# DSP_EDMA_TPTC0 register map
Vendor: Texas Instruments
Peripheral module from a debugger description file (folder DRA75x_DRA74x).
Registers are 32-bit, read-only, reset 0x0 unless marked. A register's access mark holds for its fields unless they carry their own. Offsets are as the file gives them; lines under a group give offsets from that group; [hi:lo] are bit positions; {n}, {i} and the like mark numbered series; 'fields as' and 'values as' point back to an identical list; <NAME> marks a mode.

## DSP_EDMA_TPTC0
0x00 EDMA_TPTCn_PID reset not defined — Peripheral ID Register
  [31:0] REVISION — IP Revision
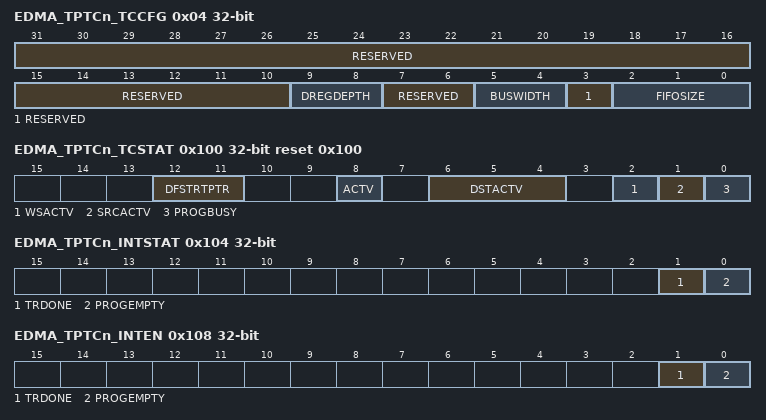
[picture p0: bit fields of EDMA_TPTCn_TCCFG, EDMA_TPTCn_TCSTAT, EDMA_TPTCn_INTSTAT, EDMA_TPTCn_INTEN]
0x04 EDMA_TPTCn_TCCFG (reset mask 0xFFFFFCC8) — TC Configuration Register
  [31:10] RESERVED — Reads return 0's
  [9:8] DREGDEPTH — Dst Register FIFO Depth Parameterization
    0=FIFODEPTH_1 (1 entry); 1=FIFODEPTH_2 (2 entries); 2=FIFODEPTH_4 (4 entries)
  [7:6] RESERVED — Reads return 0's
  [5:4] BUSWIDTH — Bus Width Parameterization
    0=BW_32BIT (32-bit); 1=BW_64BIT (64-bit); 2=BW_128BIT (128-bit)
  [3] RESERVED — Reads return 0's
  [2:0] FIFOSIZE — Fifo Size Parameterization
    0=FIFO_32_BYTE (32 byte FIFO); 1=FIFO_64_BYTE (64 byte FIFO); 2=FIFO_256_BYTE (128 byte FIFO); 3=FIFO_512_BYTE (256 byte FIFO); 4=FIFO_128_BYTE (512 byte FIFO)
0x100 EDMA_TPTCn_TCSTAT access not given reset 0x100 — TC Status Register
  [12:11] DFSTRTPTR ro — Dst FIFO Start Pointer Represents the offset to the head entry of Dst Register FIFO, in units of *entries*. Legal values = 0x0 to 0x3
  [8] ACTV ro — Channel Active Channel Active is a logical-OR of each of the *BUSY/ACTV signals. The ACTV bit must remain high through the life of a TR.
    0=Channel_is_idle; 1=Channel_is_busy
  [6:4] DSTACTV ro — Destination Active State Specifies the number of TRs that are resident in the Dst Register FIFO at a given instant. Legal values are constrained by the DSTREGDEPTH parameter.
  [2] WSACTV ro — Write Status Active
    0=Write status is not pending. Write status has been received for all previously issued write commands.; 1=Write Status is pending. Write status has not been received for all previously issued write commands.
  [1] SRCACTV ro — Source Active State
    0=TR_FIFO_(DSTFULL_0 (Source Active set is idle. Any TR written to Prog Set will immediately transition to Source Active set as long as the Dst FIFO Set is not full (DSTFULL == 1).); 1=Source Active set is busy either performing read transfers or waiting to perform read transfers for current Transfer Request
  [0] PROGBUSY ro — Program Register Set Busy
    0=Program set idle and is available for programming; 1=Program set busy. User should poll for PROGBUSY equal to '0' prior to re-programming the Program Register set.
0x104 EDMA_TPTCn_INTSTAT access not given — Interrupt Status Register
  [1] TRDONE ro — TR Done Event Status
    0=Condition_not_detected; 1=TC_TRDONE_TR._INTCLR.TRDONE_1 (Set when TC has completed a Transfer Request. TRDONE should be set when the write status is returned for the final write of a TR. Cleared when write '1' to INTCLR.TRDONE register bit.)
  [0] PROGEMPTY ro — Program Set Empty Event Status
    0=Condition_not_detected; 1=Set when Program Register set transitions to empty state. Cleared when write '1' to [0] PROGEMPTY register bit.
0x108 EDMA_TPTCn_INTEN access per field — Interrupt Enable Register
  [1] TRDONE rw — TR Done Event Enable
    0=TRDONE_Event_is_disabled; 1=TRDONE Event is enabled, and contributes to interrupt generation
  [0] PROGEMPTY rw — Program Set Empty Event Enable
    0=PROGEMPTY_Event_is_disabled; 1=PROGEMPTY Event is enabled, and contributes to interrupt generation
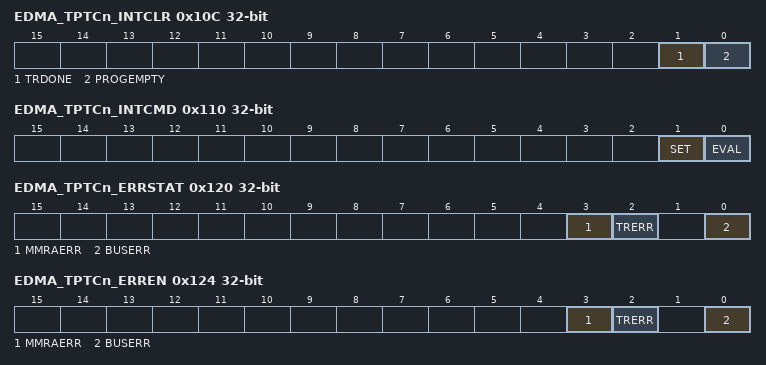
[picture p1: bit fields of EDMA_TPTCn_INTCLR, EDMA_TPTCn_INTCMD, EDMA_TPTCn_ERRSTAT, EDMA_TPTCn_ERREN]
0x10C EDMA_TPTCn_INTCLR access per field — Interrupt Clear Register
  [1] TRDONE wo — TR Done Event Clear
    0=have_no_effect; 1=Clear
  [0] PROGEMPTY wo — Program Set Empty Event Clear
    0=have_no_effect; 1=Clear
0x110 EDMA_TPTCn_INTCMD access per field — Interrupt Command Register
  [1] SET wo — Set TPTC interrupt
    0=have_no_affect; 1=SET_TPTC_1 (SET causes TPTC interrupt to be pulsed unconditionally)
  [0] EVAL wo — Evaluate state of TPTC interrupt
    0=have_no_affect; 1=TPTC_1 (causes TPTC interrupt to be pulsed if any of the bits are set to '1'.)
0x120 EDMA_TPTCn_ERRSTAT access not given — Error Status Register
  [3] MMRAERR ro — MR Address Error
    0=Condition_not_detected; 1=User attempted to read or write to invalid address configuration mMemory map. (Is only be set for non-emulation accesses). No additional error information is recorded.
  [2] TRERR ro — TR Error: TR detected that violates FIFO Mode transfer (SAM or DAM is '1') alignment rules or has ACNT or BCNT == 0. No additional error information is recorded.
  [0] BUSERR ro — Bus Error Event
    0=Condition_not_detected; 1=TC_1 (TC has detected an error code on the write response bus or read response bus. Error information is stored in Error Details Register ().)
0x124 EDMA_TPTCn_ERREN access not given — Error Enable Register
  [3] MMRAERR rw — Interrupt enable forEDMA_TPTCn_ERRSTAT[3] MMRAERR
    0=BUSERR_is_disabled; 1=MMRAERR_TPTC_1 (MMRAERR is enabled, and contributes to the TPTC error interrupt generation.)
  [2] TRERR rw — Interrupt enable forEDMA_TPTCn_ERRSTAT[2] TRERR
    0=BUSERR_is_disabled; 1=TRERR_TPTC_1 (TRERR is enabled, and contributes to the TPTC error interrupt generation.)
  [0] BUSERR rw — Interrupt enable forEDMA_TPTCn_ERRSTAT[0] BUSERR
    0=BUSERR_is_disabled; 1=BUSERR_TPTC_1 (BUSERR is enabled, and contributes to the TPTC error interrupt generation.)
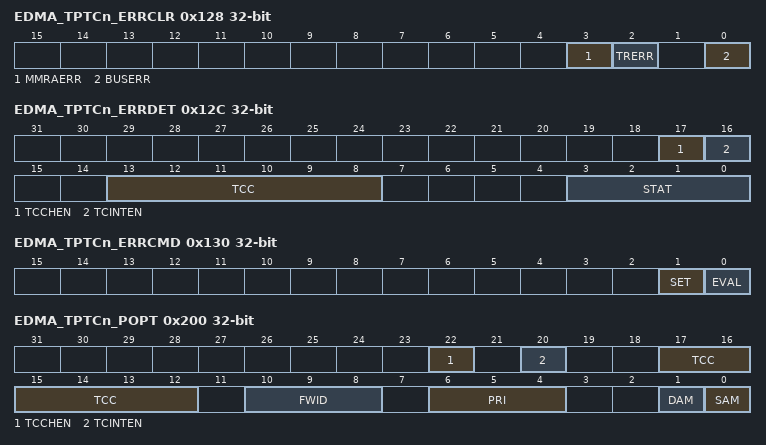
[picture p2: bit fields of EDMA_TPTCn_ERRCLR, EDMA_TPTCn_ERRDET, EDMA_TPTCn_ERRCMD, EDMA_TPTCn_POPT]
0x128 EDMA_TPTCn_ERRCLR access not given — Error Clear Register
  [3] MMRAERR wo — Interrupt clear forEDMA_TPTCn_ERRSTAT[3] MMRAERR
    0=have_no_effect; 1=MMRAERR_MMRAERR_ERRDET_1 (to clear[3] MMRAERR bit. Write of '1' to [3] MMRAERR does not clear the ERRDET register.)
  [2] TRERR wo — Interrupt clear forEDMA_TPTCn_ERRSTAT[2] TRERR
    0=have_no_effect; 1=TRERR_TRERR_ERRDET_1 (to clear[2] TRERR bit. Write of '1' to [2] TRERR does not clear the ERRDET register.)
  [0] BUSERR wo — Interrupt clear forEDMA_TPTCn_ERRSTAT[0] BUSERR
    0=have_no_effect; 1=BUSERR_BUSERR_ERRDET_1 (to clear[0] BUSERR bit Write of '1' to [0] BUSERR clears the ERRDET register.)
0x12C EDMA_TPTCn_ERRDET access not given — Error Details Register
  [17] TCCHEN ro — Contains theEDMA_TPCC_OPT_n[17] TCCHEN value programmed by the user for the Read or Write transaction that resulted in an error.
  [16] TCINTEN ro — Contains theEDMA_TPCC_OPT_n[16] TCINTEN value programmed by the user for the Read or Write transaction that resulted in an error.
  [13:8] TCC ro — Transfer Complete Code: Contains theEDMA_TPCC_OPT_n[13:8] TCC value programmed by the user for the Read or Write transaction that resulted in an error.
  [3:0] STAT ro — Transaction Status: Stores the non-zero status/error code that was detected on the read status or write status bus. MS-bit effectively serves as the read vs. write error code. If read status and write status are returned on the same cycle, then the TC chooses non-zero version. If both are non-zero then write status is treated as higher priority. Encoding of errors matches the CBA spec and is summarized here: 0xF =
0x130 EDMA_TPTCn_ERRCMD access per field — Error Command Register
  [1] SET wo — Set TPTC error interrupt
    0=have_no_affect; 1=SET_TPTC_1 (to SET causes TPTC error interrupt to be pulsed unconditionally.)
  [0] EVAL wo — Evaluate state of TPTC error interrupt Write of '1'
    0=have_no_affect; 1=EVAL_TPTC_1 (to EVAL causes TPTC error interrupt to be pulsed if any of the bits are set to '1'.)
0x140 EDMA_TPTCn_RDRATE access per field — Read Rate Register
  [2:0] RDRATE rw — Read Rate Control: Controls the number of cycles between read commands. This is a global setting that applies to all TRs for this TC.
0x200 EDMA_TPTCn_POPT access per field — Program Set Options
  [22] TCCHEN rw — Transfer complete chaining enable
    0=Transfer_complete_chaining_is_disabled; 1=Transfer_complete_chaining_is_enabled
  [20] TCINTEN rw — Transfer complete interrupt enable
    0=Transfer complete interrupt is disabled; 1=Transfer_complete_interrupt_is_enabled
  [17:12] TCC rw — Transfer Complete Code: The 6-bit code is used to set the relevant bit in CER orEDMA_TPCC_IPR of the TPCC module.
  [10:8] FWID rw — FIFO width control: Applies if either SAM or DAM is set to FIFO mode.
  [6:4] PRI rw — Transfer Priority: 0x0: Priority 0 - Highest priority 0x1: Priority 1 ... 0x7: Priority 7 - Lowest priority
  [1] DAM rw — Destination Address Mode within an array
    0=INCR,_0 (INCR, Destination addressing within an array increments.); 1=FIFO,_FIFO_1 (FIFO, Destination addressing within an array wraps around upon reaching FIFO width.)
  [0] SAM rw — Source Address Mode within an array
    0=INCR,_0 (INCR, Source addressing within an array increments.); 1=FIFO,_FIFO_1 (FIFO, Source addressing within an array wraps around upon reaching FIFO width.)
0x204 EDMA_TPTCn_PSRC rw — Program Set Source Address
  [31:0] SADDR — Source address for Program Register Set
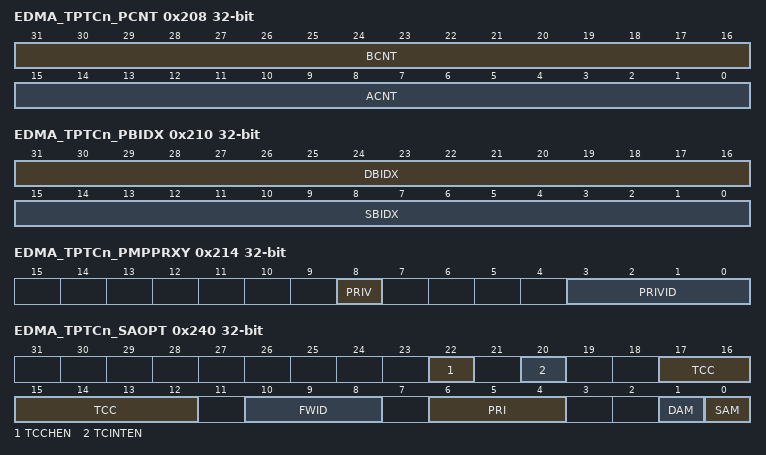
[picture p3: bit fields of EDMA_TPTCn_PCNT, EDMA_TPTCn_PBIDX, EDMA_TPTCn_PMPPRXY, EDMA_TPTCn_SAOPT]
0x208 EDMA_TPTCn_PCNT rw — Program Set Count
  [31:16] BCNT — B-Dimension count. Number of arrays to be transferred, where each array is ACNT in length.
  [15:0] ACNT — A-Dimension count. Number of bytes to be transferred in first dimension.
0x20C EDMA_TPTCn_PDST rw — Program Set Destination Address
  [31:0] DADDR — Destination address for Program Register Set
0x210 EDMA_TPTCn_PBIDX rw — Program Set B-Dim Idx
  [31:16] DBIDX — Dest B-Idx for Program Register Set: B-Idx offset between Destination arrays: Represents the offset in bytes between the starting address of each destination array (recall that there are BCNT arrays of ACNT elements). DBIDX is always used, regardless of whether DAM is Increment or FIFO mode.
  [15:0] SBIDX — Source B-Idx for Program Register Set: B-Idx offset between Source arrays: Represents the offset in bytes between the starting address of each source array (recall that there are BCNT arrays of ACNT elements). SBIDX is always used, regardless of whether SAM is Increment or FIFO mode.
0x214 EDMA_TPTCn_PMPPRXY access not given — Program Set Memory Protect Proxy
  [8] PRIV ro — Privilege Level
    0=User_level_privilege; 1=BIDX_PRIV_SA_DF_ID_PRIV_DMA_1 (Supervisor level privilege.PRIV is always updated with the value from the configuration bus privilege field on any/every write to Program Set BIDX Register (trigger register). The PRIV value for the SA Set and DF Set are copied from the value in the Program set along with the remainder of the parameter values. The privilege ID is issued on the VBusM read and write command bus such that the target endpoints can perform mMemory protection checks based on the PRIV of the external host that sets up the DMA transaction.)
  [3:0] PRIVID ro — Privilege ID: EDMA_TPTCn_PMPPRXY.PRIVID is always updated with the value from configuration bus privilege ID field on any/every write to Program Set BIDX Register (trigger register). The PRIVID value for the SA Set and DF Set are copied from the value in the Program set along with the remainder of the parameter values. The privilege ID is issued on the VBusM read and write command bus such that the target endpoints can perform mMemory protection checks based on the privid of the external host that sets up the DMA transaction.
0x240 EDMA_TPTCn_SAOPT access not given — Source Actve Set Options
  [22] TCCHEN ro — Transfer complete chaining enable
    values as EDMA_TPTCn_POPT.TCCHEN
  [20] TCINTEN ro — Transfer complete interrupt enable
    values as EDMA_TPTCn_POPT.TCINTEN
  [17:12] TCC ro — Transfer Complete Code The 6-bit code is used to set the relevant bit in EDMA_TPCC_CER or EDMA_TPCC_IPR of the TPCC module.
  [10:8] FWID ro — FIFO width control Applies if either SAM or DAM is set to FIFO mode.
  [6:4] PRI ro — Transfer Priority... .
    0=Priority_0_-_Highest_priority; 1=Priority_1; 7=Priority_7_-_Lowest_priority
  [1] DAM ro — Destination Address Mode within an array
    values as EDMA_TPTCn_POPT.DAM
  [0] SAM ro — Source Address Mode within an array
    values as EDMA_TPTCn_POPT.SAM
0x244 EDMA_TPTCn_SASRC — Source Active Set Source Address
  [31:0] SADDR — Source address for Source Active Register Set: Initial value is copied from EDMA_TPTCn_PSRC.SADDR. TC updates value according to source addressing mode (EDMA_TPCC_OPT_n.SAM) and/or source index value (BIDX.SBIDX) after each read command is issued. When a TR is complete, the final value should be the address of the last read command issued.
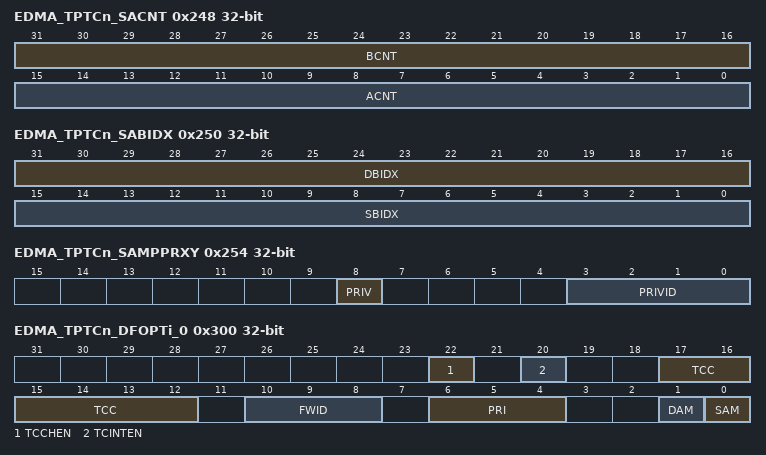
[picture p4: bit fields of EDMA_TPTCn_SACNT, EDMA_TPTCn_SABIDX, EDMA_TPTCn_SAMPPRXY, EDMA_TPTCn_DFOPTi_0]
0x248 EDMA_TPTCn_SACNT — Source Active Set Count
  [31:16] BCNT — B-Dimension count: Number of arrays to be transferred, where each array is ACNT in length. Count Remaining for Source Active Register Set. Represents the amount of data remaining to be read. Initial value is copied from EDMA_TPTCn_PCNT. TC decrements ACNT and BCNT as necessary after each read command is issued. Final value should be 0 when TR is complete.
  [15:0] ACNT — A-Dimension count: Number of bytes to be transferred in first dimension. Count Remaining for Source Active Register Set. Represents the amount of data remaining to be read. Initial value is copied from EDMA_TPTCn_PCNT. TC decrements ACNT and BCNT as necessary after each read command is issued. Final value should be 0 when TR is complete.
0x24C EDMA_TPTCn_SADST — Source Active Destination Address Register Reserved, return 0x0 w/o AERROR
  [31:0] DADDR — Destination address is not applicable for Source Active Register Set. Reads return 0x0
0x250 EDMA_TPTCn_SABIDX — Source Active Set B-Dim Idx
  [31:16] DBIDX — Destination B-Idx for Source Active Register Set. Value copied from EDMA_TPTCn_PBIDX: B-Idx offset between Destination arrays: Represents the offset in bytes between the starting address of each destination array (recall that there are BCNT arrays of ACNT elements). DBIDX is always used, regardless of whether DAM is Increment or FIFO mode.
  [15:0] SBIDX — Source B-Idx for Source Active Register Set. Value copied fromEDMA_TPTCn_PBIDX: B-Idx offset between Source arrays: Represents the offset in bytes between the starting address of each source array (recall that there are BCNT arrays of ACNT elements). SBIDX is always used, regardless of whether SAM is Increment or FIFO mode.
0x254 EDMA_TPTCn_SAMPPRXY access not given — Source Active Set Mem Protect Proxy
  [8] PRIV ro — Privilege Level
    0=User_level_privilege; 1=SAMPPRXY.PRIV_BIDX_PRIV_SA_DF_ID_PRIV_DMA_1 (Supervisor level privilege SAMPPRXY.PRIV is always updated with the value from the configuration bus privilege field on any/every write to Program Set BIDX Register (trigger register). The PRIV value for the SA Set and DF Set are copied from the value in the Program set along with the remainder of the parameter values. The privilege ID is issued on the VBusM read and write command bus such that the target endpoints can perform mMemory protection checks based on the PRIV of the external host that sets up the DMA transaction.)
  [3:0] PRIVID ro — Privilege ID SAMPPRXY.PRIVID is always updated with the value from configuration bus privilege ID field on any/every write to Program Set BIDX Register (trigger register). The PRIVID value for the SA Set and DF Set are copied from the value in the Program set along with the remainder of the parameter values. The privilege ID is issued on the VBusM read and write command bus such that the target endpoints can perform mMemory protection checks based on the privid of the external host that sets up the DMA transaction.
0x258 EDMA_TPTCn_SACNTRLD access not given — Source Active Set Count Reload
  [15:0] ACNTRLD ro — A-Cnt Reload value for Source Active Register set. Value copied from EDMA_TPTCn_PCNT[15:0] ACNT: Represents the originally programmed value of ACNT. The Reload value is used to reinitialize ACNT after each array is serviced (i.e., ACNT decrements to 0). by the Src offset in bytes between the starting address of each source array (recall that there are BCNT arrays of ACNT bytes)
0x25C EDMA_TPTCn_SASRCBREF — Source Active Set Source Address A-Reference
  [31:0] SADDRBREF — Source address reference for Source Active Register Set: Represents the starting address for the array currently being read. The next array's starting address is calculated as the 'reference address' plus the 'source b-idx' value.
0x260 EDMA_TPTCn_SADSTBREF — Source Active Destination Address B-Reference Register Reserved, return 0x0 w/o AERROR
  [31:0] DADDRBREF — Destination address reference is not applicable for Src Active Register Set. Reads return 0x0.
0x280 EDMA_TPTCn_DFCNTRLD access not given — Destination FIFO Set Count Reload
  [15:0] ACNTRLD ro — A-Cnt Reload value for Destination FIFO Register set. Value copied fromEDMA_TPTCn_PCNT[15:0] ACNT: Represents the originally programmed value of ACNT. The Reload value is used to reinitialize ACNT after each array is serviced (i.e., ACNT decrements to 0). by the Src offset in bytes between the starting address of each source array (recall that there are BCNT arrays of ACNT bytes)
0x284 EDMA_TPTCn_DFSRCBREF — Destination FIFO Set Destination Address B Reference Reserved, return 0x0 w/o AERROR
  [31:0] SADDRBREF — Source address reference is not applicable for Dst FIFO Register Set. Reads return 0x0.
0x288 EDMA_TPTCn_DFDSTBREF — Destination FIFO Set Destination Address A-Reference
  [31:0] DADDRBREF — Destination address reference for Dst FIFO Register Set: Represents the starting address for the array currently being written. The next array's starting address is calculated as the 'reference address' plus the 'dest bidx' value.
0x300 EDMA_TPTCn_DFOPTi_0 access not given — Destination FIFO Set Options
  [22] TCCHEN ro — Transfer complete chaining enable
    values as EDMA_TPTCn_POPT.TCCHEN
  [20] TCINTEN ro — Transfer complete interrupt enable
    values as EDMA_TPTCn_POPT.TCINTEN
  [17:12] TCC ro — Transfer Complete Code The 6-bit code is used to set the relevant bit in CER or EDMA_TPCC_IPR of the TPCC module.
  [10:8] FWID ro — FIFO width control Applies if either SAM or DAM is set to FIFO mode.
  [6:4] PRI ro — Transfer Priority... .
    values as EDMA_TPTCn_SAOPT.PRI
  [1] DAM ro — Destination Address Mode within an array
    0=INCR,_0 (INCR, Dst addressing within an array increments.); 1=FIFO,_FIFO_1 (FIFO, Dst addressing within an array wraps around upon reaching FIFO width.)
  [0] SAM ro — Source Address Mode within an array
    values as EDMA_TPTCn_POPT.SAM
0x304 EDMA_TPTCn_DFSRCi_0 — Destination FIFO source address register Reserved, return 0x0 w/o AERROR
  [31:0] SADDR — Source address is not applicable for Dst FIFO Register Set: Reads return 0x0.
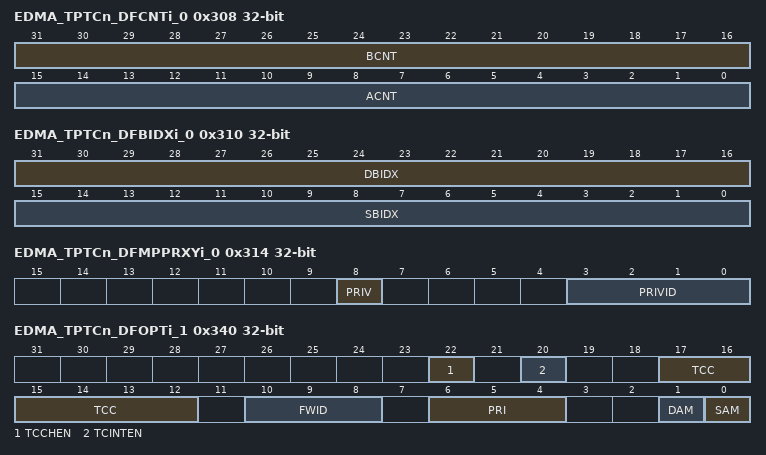
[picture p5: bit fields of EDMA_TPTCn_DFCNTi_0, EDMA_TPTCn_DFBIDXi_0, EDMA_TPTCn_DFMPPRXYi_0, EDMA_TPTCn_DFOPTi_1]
0x308 EDMA_TPTCn_DFCNTi_0 — Destination FIFO count register
  [31:16] BCNT — B-Count Remaining for Dst Register Set: Number of arrays to be transferred, where each array is ACNT in length. Represents the amount of data remaining to be written. Initial value is copied from EDMA_TPTCn_PCNT. TC decrements ACNT and BCNT as necessary after each write dataphase is issued. Final value should be 0 when TR is complete.
  [15:0] ACNT — A-Count Remaining for Dst Register Set: Number of bytes to be transferred in first dimension. Represents the amount of data remaining to be written. Initial value is copied from EDMA_TPTCn_PCNT. TC decrements ACNT and BCNT as necessary after each write dataphase is issued. Final value should be 0 when TR is complete.
0x30C EDMA_TPTCn_DFDSTi_0 — The destination FIFO destination address register
  [31:0] DADDR — Destination address for Dst FIFO Register Set: Initial value is copied from EDMA_TPTCn_PDST[31:0] DADDR. TC updates value according to destination addressing mode (EDMA_TPCC_OPT_n. SAM) and/or dest index value (BIDX. DBIDX) after each write command is issued. When a TR is complete, the final value should be the address of the last write command issued.
0x310 EDMA_TPTCn_DFBIDXi_0 — The destination FIFO B-index register
  [31:16] DBIDX — Dest B-Idx for Dest FIFO Register Set. Value copied from EDMA_TPTCn_PBIDX: B-Idx offset between Destination arrays: Represents the offset in bytes between the starting address of each destination array (recall that there are BCNT arrays of ACNT elements). DBIDX is always used, regardless of whether DAM is Increment or FIFO mode.
  [15:0] SBIDX — Dest B-Idx for Dest FIFO Register Set. Value copied fromEDMA_TPTCn_PBIDX: B-Idx offset between Source arrays: Represents the offset in bytes between the starting address of each source array (recall that there are BCNT arrays of ACNT elements). SBIDX is always used, regardless of whether SAM is Increment or FIFO mode.
0x314 EDMA_TPTCn_DFMPPRXYi_0 access not given — The destination FIFO memory protection proxy register
  [8] PRIV ro — Privilege Level
    0=User_level_privilege; 1=DFMPPRXY0.PRIV_BIDX_PRIV_SA_DF_ID_PRIV_DMA_1 (Supervisor level privilege DFMPPRXY0.PRIV is always updated with the value from the configuration bus privilege field on any/every write to Program Set BIDX Register (trigger register). The PRIV value for the SA Set and DF Set are copied from the value in the Program set along with the remainder of the parameter values. The privilege ID is issued on the VBusM read and write command bus such that the target endpoints can perform mMemory protection checks based on the PRIV of the external host that sets up the DMA transaction.)
  [3:0] PRIVID ro — Privilege ID: DFMPPRXY0.PRIVID is always updated with the value from configuration bus privilege ID field on any/every write to Program Set BIDX Register (trigger register). The PRIVID value for the SA Set and DF Set are copied from the value in the Program set along with the remainder of the parameter values. The privilege ID is issued on the VBusM read and write command bus such that the target endpoints can perform mMemory protection checks based on the privid of the external host that sets up the DMA transaction.
0x340 EDMA_TPTCn_DFOPTi_1 access not given — Destination FIFO Set Options
  fields as EDMA_TPTCn_DFOPTi_0
0x344 EDMA_TPTCn_DFSRCi_1 — Destination FIFO source address register Reserved, return 0x0 w/o AERROR
  fields as EDMA_TPTCn_DFSRCi_0
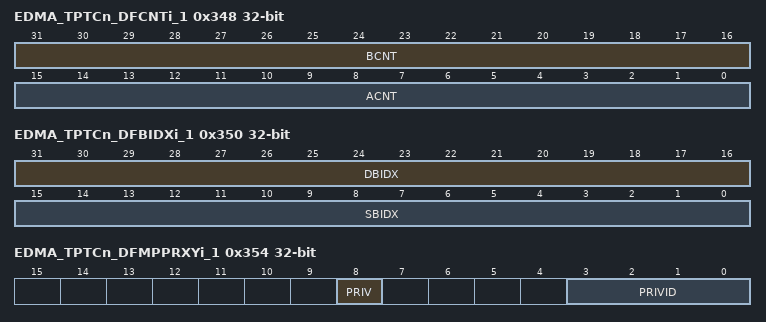
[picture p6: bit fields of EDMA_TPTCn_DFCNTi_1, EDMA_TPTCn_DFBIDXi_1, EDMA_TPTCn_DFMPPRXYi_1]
0x348 EDMA_TPTCn_DFCNTi_1 — Destination FIFO count register
  fields as EDMA_TPTCn_DFCNTi_0
0x34C EDMA_TPTCn_DFDSTi_1 — The destination FIFO destination address register
  fields as EDMA_TPTCn_DFDSTi_0
0x350 EDMA_TPTCn_DFBIDXi_1 — The destination FIFO B-index register
  fields as EDMA_TPTCn_DFBIDXi_0
0x354 EDMA_TPTCn_DFMPPRXYi_1 access not given — The destination FIFO memory protection proxy register
  fields as EDMA_TPTCn_DFMPPRXYi_0
